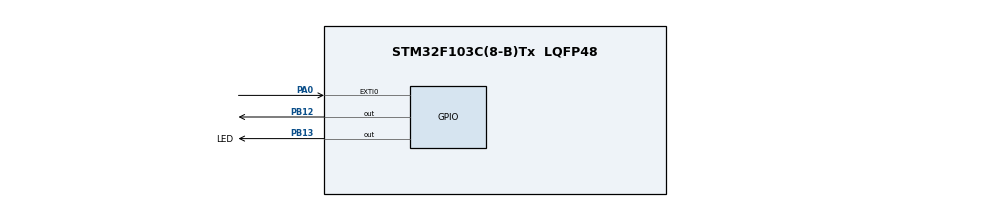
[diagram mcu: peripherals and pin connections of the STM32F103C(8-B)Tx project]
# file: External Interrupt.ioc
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Mcu.Family=STM32F1
Mcu.Name=STM32F103C(8-B)Tx
Mcu.Package=LQFP48
NVIC.EXTI0_IRQn=true\:0\:0\:false\:false\:true
NVIC.PriorityGroup=NVIC_PRIORITYGROUP_4
PA0-WKUP.GPIO_ModeDefaultEXTI=GPIO_MODE_IT_RISING_FALLING
PA0-WKUP.GPIO_PuPd=GPIO_PULLDOWN
PA0-WKUP.Signal=GPXTI0
PB12.Signal=GPIO_Output
PB13.GPIO_Label=LED
PB13.Signal=GPIO_Output
ProjectManager.HeapSize=0x200
ProjectManager.StackSize=0x400
ProjectManager.TargetToolchain=MDK-ARM V4
RCC.APB1Freq_Value=8000000
RCC.APB2Freq_Value=8000000
board=External Interrupt

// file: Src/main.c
/**
  ******************************************************************************
  * File Name          : main.c
  * Description        : Main program body
  ******************************************************************************
  *
  * COPYRIGHT(c) 2016 STMicroelectronics
  *
  * Redistribution and use in source and binary forms, with or without modification,
  * are permitted provided that the following conditions are met:
  *   1. Redistributions of source code must retain the above copyright notice,
  *      this list of conditions and the following disclaimer.
  *   2. Redistributions in binary form must reproduce the above copyright notice,
  *      this list of conditions and the following disclaimer in the documentation
  *      and/or other materials provided with the distribution.
  *   3. Neither the name of STMicroelectronics nor the names of its contributors
  *      may be used to endorse or promote products derived from this software
  *      without specific prior written permission.
  *
  * THIS SOFTWARE IS PROVIDED BY THE COPYRIGHT HOLDERS AND CONTRIBUTORS "AS IS"
  * AND ANY EXPRESS OR IMPLIED WARRANTIES, INCLUDING, BUT NOT LIMITED TO, THE
  * IMPLIED WARRANTIES OF MERCHANTABILITY AND FITNESS FOR A PARTICULAR PURPOSE ARE
  * DISCLAIMED. IN NO EVENT SHALL THE COPYRIGHT HOLDER OR CONTRIBUTORS BE LIABLE
  * FOR ANY DIRECT, INDIRECT, INCIDENTAL, SPECIAL, EXEMPLARY, OR CONSEQUENTIAL
  * DAMAGES (INCLUDING, BUT NOT LIMITED TO, PROCUREMENT OF SUBSTITUTE GOODS OR
  * SERVICES; LOSS OF USE, DATA, OR PROFITS; OR BUSINESS INTERRUPTION) HOWEVER
  * CAUSED AND ON ANY THEORY OF LIABILITY, WHETHER IN CONTRACT, STRICT LIABILITY,
  * OR TORT (INCLUDING NEGLIGENCE OR OTHERWISE) ARISING IN ANY WAY OUT OF THE USE
  * OF THIS SOFTWARE, EVEN IF ADVISED OF THE POSSIBILITY OF SUCH DAMAGE.
  *
  ******************************************************************************
  */
#include "stm32f1xx_hal.h"

/* USER CODE BEGIN PV */
/* Private variables ---------------------------------------------------------*/

/* USER CODE END PV */

void SystemClock_Config(void);
static void MX_GPIO_Init(void);

/* USER CODE BEGIN PFP */
/* Private function prototypes -----------------------------------------------*/

/* USER CODE END PFP */

int main(void)
{

  /* MCU Configuration----------------------------------------------------------*/

  /* Reset of all peripherals, Initializes the Flash interface and the Systick. */
  HAL_Init();

  /* Configure the system clock */
  SystemClock_Config();

  /* Initialize all configured peripherals */
  MX_GPIO_Init();

  /* Infinite loop */
  while (1)
  {

  /* USER CODE BEGIN 3 */
	//HAL_GPIO_WritePin(GPIOB,GPIO_PIN_12,HAL_GPIO_ReadPin(GPIOA,GPIO_PIN_0));	//Kiem tra nut nhan hay khong, neu nhan thi sang led do, khong thi tat LED
	//Tam thoi trong file main chi co chop tat LED xanh lien tuc 3s
		HAL_GPIO_TogglePin(GPIOB, GPIO_PIN_13);	// dong thoi chop tat LED xanh
	HAL_Delay(3000); // Tang thoi gian delay len 3s xem hien tuong nhu the nao
	// Nhin ra thi moi thay hien tuong la an nut mai ma khong thay bat tat LED, co hien tuong tre qua nhieu
	// Chung ta thu voi ngat o day se co tac dung khac biet, ban se hieu tai sao lai dung ngat, hieu qua no duoc the hien ngay
  }
  /* USER CODE END 3 */

}

/** System Clock Configuration
*/
void SystemClock_Config(void)
{

  RCC_OscInitTypeDef RCC_OscInitStruct;
  RCC_ClkInitTypeDef RCC_ClkInitStruct;

  RCC_OscInitStruct.OscillatorType = RCC_OSCILLATORTYPE_HSI;
  RCC_OscInitStruct.HSIState = RCC_HSI_ON;
  RCC_OscInitStruct.HSICalibrationValue = 16;
  RCC_OscInitStruct.PLL.PLLState = RCC_PLL_NONE;
  HAL_RCC_OscConfig(&RCC_OscInitStruct);

  RCC_ClkInitStruct.ClockType = RCC_CLOCKTYPE_HCLK|RCC_CLOCKTYPE_SYSCLK
                              |RCC_CLOCKTYPE_PCLK1|RCC_CLOCKTYPE_PCLK2;
  RCC_ClkInitStruct.SYSCLKSource = RCC_SYSCLKSOURCE_HSI;
  RCC_ClkInitStruct.AHBCLKDivider = RCC_SYSCLK_DIV1;
  RCC_ClkInitStruct.APB1CLKDivider = RCC_HCLK_DIV1;
  RCC_ClkInitStruct.APB2CLKDivider = RCC_HCLK_DIV1;
  HAL_RCC_ClockConfig(&RCC_ClkInitStruct, FLASH_LATENCY_0);

  HAL_SYSTICK_Config(HAL_RCC_GetHCLKFreq()/1000);

  HAL_SYSTICK_CLKSourceConfig(SYSTICK_CLKSOURCE_HCLK);

  /* SysTick_IRQn interrupt configuration */
  HAL_NVIC_SetPriority(SysTick_IRQn, 0, 0);
}

/** Configure pins as
        * Analog
        * Input
        * Output
        * EVENT_OUT
        * EXTI
*/
void MX_GPIO_Init(void)
{

  GPIO_InitTypeDef GPIO_InitStruct;

  /* GPIO Ports Clock Enable */
  __HAL_RCC_GPIOA_CLK_ENABLE();
  __HAL_RCC_GPIOB_CLK_ENABLE();

  /*Configure GPIO pin : PA0 */
  GPIO_InitStruct.Pin = GPIO_PIN_0;
  GPIO_InitStruct.Mode = GPIO_MODE_IT_RISING_FALLING;
  GPIO_InitStruct.Pull = GPIO_PULLDOWN;
  HAL_GPIO_Init(GPIOA, &GPIO_InitStruct);

  /*Configure GPIO pins : PB12 LED_Pin */
  GPIO_InitStruct.Pin = GPIO_PIN_12|LED_Pin;
  GPIO_InitStruct.Mode = GPIO_MODE_OUTPUT_PP;
  GPIO_InitStruct.Speed = GPIO_SPEED_FREQ_LOW;
  HAL_GPIO_Init(GPIOB, &GPIO_InitStruct);

  /*Configure GPIO pin Output Level */
  HAL_GPIO_WritePin(GPIOB, GPIO_PIN_12|LED_Pin, GPIO_PIN_RESET);

  /* EXTI interrupt init*/
  HAL_NVIC_SetPriority(EXTI0_IRQn, 0, 0);
  HAL_NVIC_EnableIRQ(EXTI0_IRQn);

}

/************************ (C) COPYRIGHT STMicroelectronics *****END OF FILE****/
